# CTRL_MODULE_CORE register map
Vendor: Texas Instruments
Registers are 32-bit, access per field, reset 0x0 unless marked. A register's access mark holds for its fields unless they carry their own. Offsets are as the file gives them; [hi:lo] are bit positions; 'fields as' and 'values as' point back to an identical list.

## CTRL_MODULE_CORE (part 9 of 12)
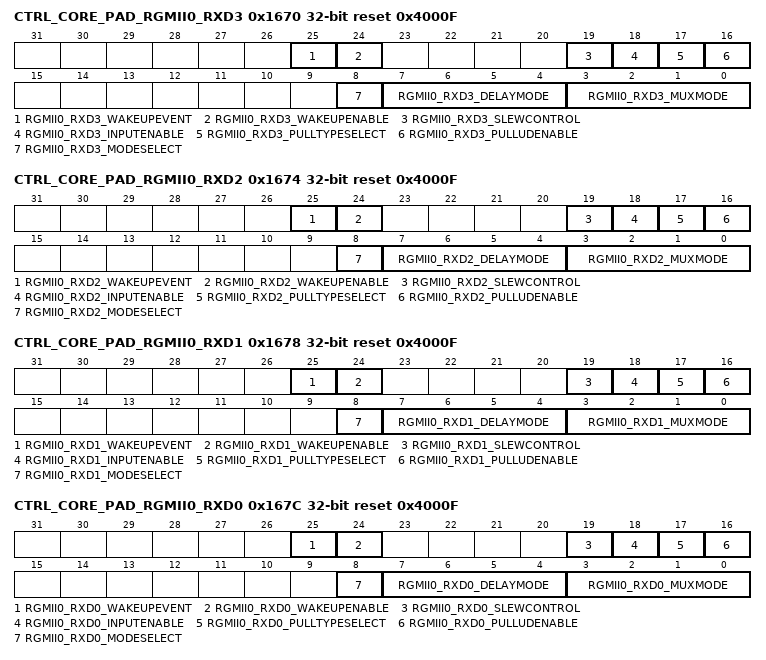
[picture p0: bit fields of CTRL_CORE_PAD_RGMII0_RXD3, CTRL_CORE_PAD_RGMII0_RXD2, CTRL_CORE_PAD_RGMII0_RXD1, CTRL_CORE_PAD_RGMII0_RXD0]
0x1670 CTRL_CORE_PAD_RGMII0_RXD3 reset 0x4000F
  [25] RGMII0_RXD3_WAKEUPEVENT ro
    0=NOWAKEUP (No wakeup event detected); 1=WAKEUP (Wakeup event detected)
  [24] RGMII0_RXD3_WAKEUPENABLE rw
    0=DISABLE (Wakeup is disabled); 1=ENABLE (Wakeup is enabled)
  [19] RGMII0_RXD3_SLEWCONTROL rw
    0=FAST_SLEW (Fast slew is selected); 1=SLOW_SLEW (Slow slew is selected)
  [18] RGMII0_RXD3_INPUTENABLE rw
    0=DISABLE (Receive mode is disabled); 1=ENABLE (Receive mode is enabled)
  [17] RGMII0_RXD3_PULLTYPESELECT rw
    0=PULL_DOWN (Pull Down is selected); 1=PULL_UP (Pull Up is selected)
  [16] RGMII0_RXD3_PULLUDENABLE rw
    0=ENABLE (Enables weak Pull Up/Down); 1=DISABLE (Disables weak Pull Up/Down)
  [8] RGMII0_RXD3_MODESELECT rw — Selects between the Default IO Timing Mode and a Virtual or Manual IO Timing Mode. Refer to the device Data Manual for definition of the required settings for a given mode of operation. When this bit is 0b1, a Virtual IO Timing Mode can be selected via the DELAYMODE field of this register, as described in, Virtual IO Timing Modes. Manual IO Timing Modes are selected via the procedure described in , Manual IO Timing Modes.
    0=MUX_MODE (Default IO Timing Mode is used); 1=DELAY_MODE (A Virtual or Manual IO Timing Mode is used)
  [7:4] RGMII0_RXD3_DELAYMODE rw — This bit field selects the Virtual Timing Mode used when the MODESELECT bit is set to 0b1. See, Virtual IO Timing Modes for details.
  [3:0] RGMII0_RXD3_MUXMODE rw
    0=RGMII0_RXD3; 2=RMII1_TXD0; 3=MII0_TXD2; 4=VIN2A_D7; 5=VIN4B_D7; 11=PR1_MII0_TXD2; 12=PR2_PRU1_GPI13; 13=PR2_PRU1_GPO13; 14=GPIO5_28; 15=DRIVER OFF
0x1674 CTRL_CORE_PAD_RGMII0_RXD2 reset 0x4000F
  [25] RGMII0_RXD2_WAKEUPEVENT ro
    values as CTRL_CORE_PAD_RGMII0_RXD3.RGMII0_RXD3_WAKEUPEVENT
  [24] RGMII0_RXD2_WAKEUPENABLE rw
    0=DISABLE (Wakeup is disabled); 1=ENABLE (Wakeup is enabled)
  [19] RGMII0_RXD2_SLEWCONTROL rw
    values as CTRL_CORE_PAD_RGMII0_RXD3.RGMII0_RXD3_SLEWCONTROL
  [18] RGMII0_RXD2_INPUTENABLE rw
    values as CTRL_CORE_PAD_RGMII0_RXD3.RGMII0_RXD3_INPUTENABLE
  [17] RGMII0_RXD2_PULLTYPESELECT rw
    values as CTRL_CORE_PAD_RGMII0_RXD3.RGMII0_RXD3_PULLTYPESELECT
  [16] RGMII0_RXD2_PULLUDENABLE rw
    values as CTRL_CORE_PAD_RGMII0_RXD3.RGMII0_RXD3_PULLUDENABLE
  [8] RGMII0_RXD2_MODESELECT rw — Selects between the Default IO Timing Mode and a Virtual or Manual IO Timing Mode. Refer to the device Data Manual for definition of the required settings for a given mode of operation. When this bit is 0b1, a Virtual IO Timing Mode can be selected via the DELAYMODE field of this register, as described in, Virtual IO Timing Modes. Manual IO Timing Modes are selected via the procedure described in , Manual IO Timing Modes.
    values as CTRL_CORE_PAD_RGMII0_RXD3.RGMII0_RXD3_MODESELECT
  [7:4] RGMII0_RXD2_DELAYMODE rw — This bit field selects the Virtual Timing Mode used when the MODESELECT bit is set to 0b1. See, Virtual IO Timing Modes for details.
  [3:0] RGMII0_RXD2_MUXMODE rw
    0=RGMII0_RXD2; 1=RMII0_TXEN; 3=MII0_TXEN; 4=VIN2A_D8; 11=PR1_MII0_TXEN; 12=PR2_PRU1_GPI14; 13=PR2_PRU1_GPO14; 14=GPIO5_29; 15=DRIVER OFF
0x1678 CTRL_CORE_PAD_RGMII0_RXD1 reset 0x4000F
  [25] RGMII0_RXD1_WAKEUPEVENT ro
    values as CTRL_CORE_PAD_RGMII0_RXD3.RGMII0_RXD3_WAKEUPEVENT
  [24] RGMII0_RXD1_WAKEUPENABLE rw
    0=DISABLE (Wakeup is disabled); 1=ENABLE (Wakeup is enabled)
  [19] RGMII0_RXD1_SLEWCONTROL rw
    values as CTRL_CORE_PAD_RGMII0_RXD3.RGMII0_RXD3_SLEWCONTROL
  [18] RGMII0_RXD1_INPUTENABLE rw
    values as CTRL_CORE_PAD_RGMII0_RXD3.RGMII0_RXD3_INPUTENABLE
  [17] RGMII0_RXD1_PULLTYPESELECT rw
    values as CTRL_CORE_PAD_RGMII0_RXD3.RGMII0_RXD3_PULLTYPESELECT
  [16] RGMII0_RXD1_PULLUDENABLE rw
    values as CTRL_CORE_PAD_RGMII0_RXD3.RGMII0_RXD3_PULLUDENABLE
  [8] RGMII0_RXD1_MODESELECT rw — Selects between the Default IO Timing Mode and a Virtual or Manual IO Timing Mode. Refer to the device Data Manual for definition of the required settings for a given mode of operation. When this bit is 0b1, a Virtual IO Timing Mode can be selected via the DELAYMODE field of this register, as described in, Virtual IO Timing Modes. Manual IO Timing Modes are selected via the procedure described in , Manual IO Timing Modes.
    values as CTRL_CORE_PAD_RGMII0_RXD3.RGMII0_RXD3_MODESELECT
  [7:4] RGMII0_RXD1_DELAYMODE rw — This bit field selects the Virtual Timing Mode used when the MODESELECT bit is set to 0b1. See, Virtual IO Timing Modes for details.
  [3:0] RGMII0_RXD1_MUXMODE rw
    0=RGMII0_RXD1; 1=RMII0_TXD1; 3=MII0_TXD1; 4=VIN2A_D9; 11=PR1_MII0_TXD1; 12=PR2_PRU1_GPI15; 13=PR2_PRU1_GPO15; 14=GPIO5_30; 15=DRIVER OFF
0x167C CTRL_CORE_PAD_RGMII0_RXD0 reset 0x4000F
  [25] RGMII0_RXD0_WAKEUPEVENT ro
    values as CTRL_CORE_PAD_RGMII0_RXD3.RGMII0_RXD3_WAKEUPEVENT
  [24] RGMII0_RXD0_WAKEUPENABLE rw
    0=DISABLE (Wakeup is disabled); 1=ENABLE (Wakeup is enabled)
  [19] RGMII0_RXD0_SLEWCONTROL rw
    values as CTRL_CORE_PAD_RGMII0_RXD3.RGMII0_RXD3_SLEWCONTROL
  [18] RGMII0_RXD0_INPUTENABLE rw
    values as CTRL_CORE_PAD_RGMII0_RXD3.RGMII0_RXD3_INPUTENABLE
  [17] RGMII0_RXD0_PULLTYPESELECT rw
    values as CTRL_CORE_PAD_RGMII0_RXD3.RGMII0_RXD3_PULLTYPESELECT
  [16] RGMII0_RXD0_PULLUDENABLE rw
    values as CTRL_CORE_PAD_RGMII0_RXD3.RGMII0_RXD3_PULLUDENABLE
  [8] RGMII0_RXD0_MODESELECT rw — Selects between the Default IO Timing Mode and a Virtual or Manual IO Timing Mode. Refer to the device Data Manual for definition of the required settings for a given mode of operation. When this bit is 0b1, a Virtual IO Timing Mode can be selected via the DELAYMODE field of this register, as described in, Virtual IO Timing Modes. Manual IO Timing Modes are selected via the procedure described in , Manual IO Timing Modes.
    values as CTRL_CORE_PAD_RGMII0_RXD3.RGMII0_RXD3_MODESELECT
  [7:4] RGMII0_RXD0_DELAYMODE rw — This bit field selects the Virtual Timing Mode used when the MODESELECT bit is set to 0b1. See, Virtual IO Timing Modes for details.
  [3:0] RGMII0_RXD0_MUXMODE rw
    0=RGMII0_RXD0; 1=RMII0_TXD0; 3=MII0_TXD0; 4=VIN2A_FLD0; 5=VIN4B_FLD1; 11=PR1_MII0_TXD0; 12=PR2_PRU1_GPI16; 13=PR2_PRU1_GPO16; 14=GPIO5_31; 15=DRIVER OFF
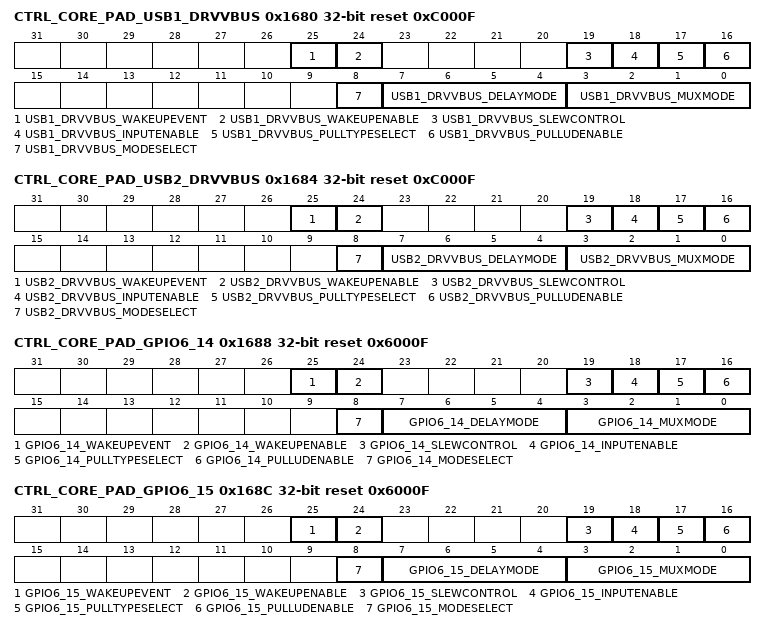
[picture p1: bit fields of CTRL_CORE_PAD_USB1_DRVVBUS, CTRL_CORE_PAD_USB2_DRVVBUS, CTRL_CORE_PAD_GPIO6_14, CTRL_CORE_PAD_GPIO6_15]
0x1680 CTRL_CORE_PAD_USB1_DRVVBUS reset 0xC000F
  [25] USB1_DRVVBUS_WAKEUPEVENT ro
    values as CTRL_CORE_PAD_RGMII0_RXD3.RGMII0_RXD3_WAKEUPEVENT
  [24] USB1_DRVVBUS_WAKEUPENABLE rw
    0=DISABLE (Wakeup is disabled); 1=ENABLE (Wakeup is enabled)
  [19] USB1_DRVVBUS_SLEWCONTROL rw
    values as CTRL_CORE_PAD_RGMII0_RXD3.RGMII0_RXD3_SLEWCONTROL
  [18] USB1_DRVVBUS_INPUTENABLE rw
    values as CTRL_CORE_PAD_RGMII0_RXD3.RGMII0_RXD3_INPUTENABLE
  [17] USB1_DRVVBUS_PULLTYPESELECT rw
    values as CTRL_CORE_PAD_RGMII0_RXD3.RGMII0_RXD3_PULLTYPESELECT
  [16] USB1_DRVVBUS_PULLUDENABLE rw
    values as CTRL_CORE_PAD_RGMII0_RXD3.RGMII0_RXD3_PULLUDENABLE
  [8] USB1_DRVVBUS_MODESELECT rw — Selects between the Default IO Timing Mode and a Virtual or Manual IO Timing Mode. Refer to the device Data Manual for definition of the required settings for a given mode of operation. When this bit is 0b1, a Virtual IO Timing Mode can be selected via the DELAYMODE field of this register, as described in, Virtual IO Timing Modes. Manual IO Timing Modes are selected via the procedure described in , Manual IO Timing Modes.
    values as CTRL_CORE_PAD_RGMII0_RXD3.RGMII0_RXD3_MODESELECT
  [7:4] USB1_DRVVBUS_DELAYMODE rw — This bit field selects the Virtual Timing Mode used when the MODESELECT bit is set to 0b1. See, Virtual IO Timing Modes for details.
  [3:0] USB1_DRVVBUS_MUXMODE rw
    0=USB1_DRVVBUS; 7=TIMER16; 14=GPIO6_12; 15=DRIVER OFF
0x1684 CTRL_CORE_PAD_USB2_DRVVBUS reset 0xC000F
  [25] USB2_DRVVBUS_WAKEUPEVENT ro
    values as CTRL_CORE_PAD_RGMII0_RXD3.RGMII0_RXD3_WAKEUPEVENT
  [24] USB2_DRVVBUS_WAKEUPENABLE rw
    0=DISABLE (Wakeup is disabled); 1=ENABLE (Wakeup is enabled)
  [19] USB2_DRVVBUS_SLEWCONTROL rw
    values as CTRL_CORE_PAD_RGMII0_RXD3.RGMII0_RXD3_SLEWCONTROL
  [18] USB2_DRVVBUS_INPUTENABLE rw
    values as CTRL_CORE_PAD_RGMII0_RXD3.RGMII0_RXD3_INPUTENABLE
  [17] USB2_DRVVBUS_PULLTYPESELECT rw
    values as CTRL_CORE_PAD_RGMII0_RXD3.RGMII0_RXD3_PULLTYPESELECT
  [16] USB2_DRVVBUS_PULLUDENABLE rw
    values as CTRL_CORE_PAD_RGMII0_RXD3.RGMII0_RXD3_PULLUDENABLE
  [8] USB2_DRVVBUS_MODESELECT rw — Selects between the Default IO Timing Mode and a Virtual or Manual IO Timing Mode. Refer to the device Data Manual for definition of the required settings for a given mode of operation. When this bit is 0b1, a Virtual IO Timing Mode can be selected via the DELAYMODE field of this register, as described in, Virtual IO Timing Modes. Manual IO Timing Modes are selected via the procedure described in , Manual IO Timing Modes.
    values as CTRL_CORE_PAD_RGMII0_RXD3.RGMII0_RXD3_MODESELECT
  [7:4] USB2_DRVVBUS_DELAYMODE rw — This bit field selects the Virtual Timing Mode used when the MODESELECT bit is set to 0b1. See, Virtual IO Timing Modes for details.
  [3:0] USB2_DRVVBUS_MUXMODE rw
    0=USB2_DRVVBUS; 7=TIMER15; 14=GPIO6_13; 15=DRIVER OFF
0x1688 CTRL_CORE_PAD_GPIO6_14 reset 0x6000F
  [25] GPIO6_14_WAKEUPEVENT ro
    values as CTRL_CORE_PAD_RGMII0_RXD3.RGMII0_RXD3_WAKEUPEVENT
  [24] GPIO6_14_WAKEUPENABLE rw
    0=DISABLE (Wakeup is disabled); 1=ENABLE (Wakeup is enabled)
  [19] GPIO6_14_SLEWCONTROL rw
    values as CTRL_CORE_PAD_RGMII0_RXD3.RGMII0_RXD3_SLEWCONTROL
  [18] GPIO6_14_INPUTENABLE rw
    values as CTRL_CORE_PAD_RGMII0_RXD3.RGMII0_RXD3_INPUTENABLE
  [17] GPIO6_14_PULLTYPESELECT rw
    values as CTRL_CORE_PAD_RGMII0_RXD3.RGMII0_RXD3_PULLTYPESELECT
  [16] GPIO6_14_PULLUDENABLE rw
    values as CTRL_CORE_PAD_RGMII0_RXD3.RGMII0_RXD3_PULLUDENABLE
  [8] GPIO6_14_MODESELECT rw — Selects between the Default IO Timing Mode and a Virtual or Manual IO Timing Mode. Refer to the device Data Manual for definition of the required settings for a given mode of operation. When this bit is 0b1, a Virtual IO Timing Mode can be selected via the DELAYMODE field of this register, as described in, Virtual IO Timing Modes. Manual IO Timing Modes are selected via the procedure described in , Manual IO Timing Modes.
    values as CTRL_CORE_PAD_RGMII0_RXD3.RGMII0_RXD3_MODESELECT
  [7:4] GPIO6_14_DELAYMODE rw — This bit field selects the Virtual Timing Mode used when the MODESELECT bit is set to 0b1. See, Virtual IO Timing Modes for details.
  [3:0] GPIO6_14_MUXMODE rw
    0=GPIO6_14; 1=MCASP1_AXR8; 2=DCAN2_TX; 3=UART10_RXD; 6=VOUT2_HSYNC; 8=VIN4A_HSYNC0; 9=I2C3_SDA; 10=TIMER1; 14=GPIO6_14; 15=DRIVER OFF
0x168C CTRL_CORE_PAD_GPIO6_15 reset 0x6000F
  [25] GPIO6_15_WAKEUPEVENT ro
    values as CTRL_CORE_PAD_RGMII0_RXD3.RGMII0_RXD3_WAKEUPEVENT
  [24] GPIO6_15_WAKEUPENABLE rw
    0=DISABLE (Wakeup is disabled); 1=ENABLE (Wakeup is enabled)
  [19] GPIO6_15_SLEWCONTROL rw
    values as CTRL_CORE_PAD_RGMII0_RXD3.RGMII0_RXD3_SLEWCONTROL
  [18] GPIO6_15_INPUTENABLE rw
    values as CTRL_CORE_PAD_RGMII0_RXD3.RGMII0_RXD3_INPUTENABLE
  [17] GPIO6_15_PULLTYPESELECT rw
    values as CTRL_CORE_PAD_RGMII0_RXD3.RGMII0_RXD3_PULLTYPESELECT
  [16] GPIO6_15_PULLUDENABLE rw
    values as CTRL_CORE_PAD_RGMII0_RXD3.RGMII0_RXD3_PULLUDENABLE
  [8] GPIO6_15_MODESELECT rw — Selects between the Default IO Timing Mode and a Virtual or Manual IO Timing Mode. Refer to the device Data Manual for definition of the required settings for a given mode of operation. When this bit is 0b1, a Virtual IO Timing Mode can be selected via the DELAYMODE field of this register, as described in, Virtual IO Timing Modes. Manual IO Timing Modes are selected via the procedure described in , Manual IO Timing Modes.
    values as CTRL_CORE_PAD_RGMII0_RXD3.RGMII0_RXD3_MODESELECT
  [7:4] GPIO6_15_DELAYMODE rw — This bit field selects the Virtual Timing Mode used when the MODESELECT bit is set to 0b1. See, Virtual IO Timing Modes for details.
  [3:0] GPIO6_15_MUXMODE rw
    0=GPIO6_15; 1=MCASP1_AXR9; 2=DCAN2_RX; 3=UART10_TXD; 6=VOUT2_VSYNC; 8=VIN4A_VSYNC0; 9=I2C3_SCL; 10=TIMER2; 14=GPIO6_15; 15=DRIVER OFF
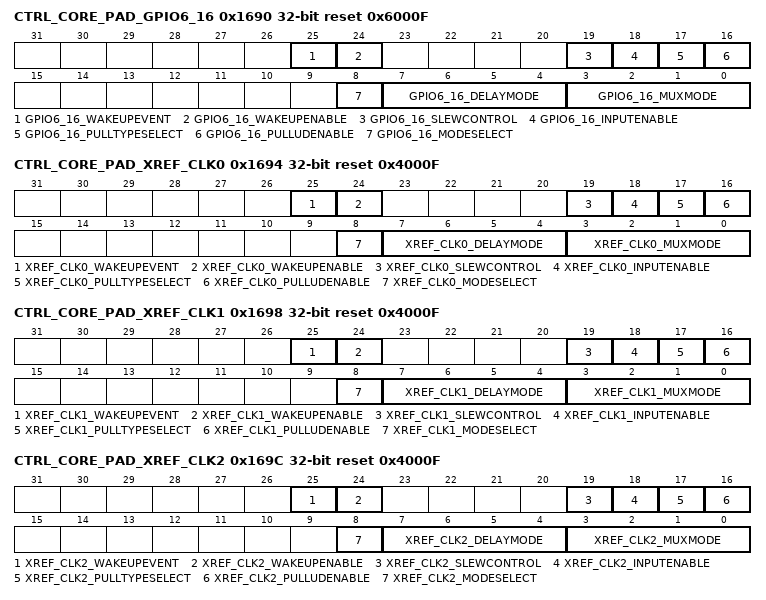
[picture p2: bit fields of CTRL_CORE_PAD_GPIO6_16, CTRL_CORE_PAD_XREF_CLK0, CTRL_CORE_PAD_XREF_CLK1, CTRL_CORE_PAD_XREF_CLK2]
0x1690 CTRL_CORE_PAD_GPIO6_16 reset 0x6000F
  [25] GPIO6_16_WAKEUPEVENT ro
    values as CTRL_CORE_PAD_RGMII0_RXD3.RGMII0_RXD3_WAKEUPEVENT
  [24] GPIO6_16_WAKEUPENABLE rw
    0=DISABLE (Wakeup is disabled); 1=ENABLE (Wakeup is enabled)
  [19] GPIO6_16_SLEWCONTROL rw
    values as CTRL_CORE_PAD_RGMII0_RXD3.RGMII0_RXD3_SLEWCONTROL
  [18] GPIO6_16_INPUTENABLE rw
    values as CTRL_CORE_PAD_RGMII0_RXD3.RGMII0_RXD3_INPUTENABLE
  [17] GPIO6_16_PULLTYPESELECT rw
    values as CTRL_CORE_PAD_RGMII0_RXD3.RGMII0_RXD3_PULLTYPESELECT
  [16] GPIO6_16_PULLUDENABLE rw
    values as CTRL_CORE_PAD_RGMII0_RXD3.RGMII0_RXD3_PULLUDENABLE
  [8] GPIO6_16_MODESELECT rw — Selects between the Default IO Timing Mode and a Virtual or Manual IO Timing Mode. Refer to the device Data Manual for definition of the required settings for a given mode of operation. When this bit is 0b1, a Virtual IO Timing Mode can be selected via the DELAYMODE field of this register, as described in, Virtual IO Timing Modes. Manual IO Timing Modes are selected via the procedure described in , Manual IO Timing Modes.
    values as CTRL_CORE_PAD_RGMII0_RXD3.RGMII0_RXD3_MODESELECT
  [7:4] GPIO6_16_DELAYMODE rw — This bit field selects the Virtual Timing Mode used when the MODESELECT bit is set to 0b1. See, Virtual IO Timing Modes for details.
  [3:0] GPIO6_16_MUXMODE rw
    0=GPIO6_16; 1=MCASP1_AXR10; 6=VOUT2_FLD; 8=VIN4A_FLD0; 9=CLKOUT1; 10=TIMER3; 14=GPIO6_16; 15=DRIVER OFF
0x1694 CTRL_CORE_PAD_XREF_CLK0 reset 0x4000F
  [25] XREF_CLK0_WAKEUPEVENT ro
    values as CTRL_CORE_PAD_RGMII0_RXD3.RGMII0_RXD3_WAKEUPEVENT
  [24] XREF_CLK0_WAKEUPENABLE rw
    0=DISABLE (Wakeup is disabled); 1=ENABLE (Wakeup is enabled)
  [19] XREF_CLK0_SLEWCONTROL rw
    values as CTRL_CORE_PAD_RGMII0_RXD3.RGMII0_RXD3_SLEWCONTROL
  [18] XREF_CLK0_INPUTENABLE rw
    values as CTRL_CORE_PAD_RGMII0_RXD3.RGMII0_RXD3_INPUTENABLE
  [17] XREF_CLK0_PULLTYPESELECT rw
    values as CTRL_CORE_PAD_RGMII0_RXD3.RGMII0_RXD3_PULLTYPESELECT
  [16] XREF_CLK0_PULLUDENABLE rw
    values as CTRL_CORE_PAD_RGMII0_RXD3.RGMII0_RXD3_PULLUDENABLE
  [8] XREF_CLK0_MODESELECT rw — Selects between the Default IO Timing Mode and a Virtual or Manual IO Timing Mode. Refer to the device Data Manual for definition of the required settings for a given mode of operation. When this bit is 0b1, a Virtual IO Timing Mode can be selected via the DELAYMODE field of this register, as described in, Virtual IO Timing Modes. Manual IO Timing Modes are selected via the procedure described in , Manual IO Timing Modes.
    values as CTRL_CORE_PAD_RGMII0_RXD3.RGMII0_RXD3_MODESELECT
  [7:4] XREF_CLK0_DELAYMODE rw — This bit field selects the Virtual Timing Mode used when the MODESELECT bit is set to 0b1. See, Virtual IO Timing Modes for details.
  [3:0] XREF_CLK0_MUXMODE rw
    0=XREF_CLK0; 1=MCASP2_AXR8; 2=MCASP1_AXR4; 3=MCASP1_AHCLKX; 4=MCASP5_AHCLKX; 7=VIN6A_D0; 8=HDQ0; 9=CLKOUT2; 10=TIMER13; 11=PR2_MII1_COL; 12=PR2_PRU1_GPI5; 13=PR2_PRU1_GPO5; 14=GPIO6_17; 15=DRIVER OFF
0x1698 CTRL_CORE_PAD_XREF_CLK1 reset 0x4000F
  [25] XREF_CLK1_WAKEUPEVENT ro
    values as CTRL_CORE_PAD_RGMII0_RXD3.RGMII0_RXD3_WAKEUPEVENT
  [24] XREF_CLK1_WAKEUPENABLE rw
    0=DISABLE (Wakeup is disabled); 1=ENABLE (Wakeup is enabled)
  [19] XREF_CLK1_SLEWCONTROL rw
    values as CTRL_CORE_PAD_RGMII0_RXD3.RGMII0_RXD3_SLEWCONTROL
  [18] XREF_CLK1_INPUTENABLE rw
    values as CTRL_CORE_PAD_RGMII0_RXD3.RGMII0_RXD3_INPUTENABLE
  [17] XREF_CLK1_PULLTYPESELECT rw
    values as CTRL_CORE_PAD_RGMII0_RXD3.RGMII0_RXD3_PULLTYPESELECT
  [16] XREF_CLK1_PULLUDENABLE rw
    values as CTRL_CORE_PAD_RGMII0_RXD3.RGMII0_RXD3_PULLUDENABLE
  [8] XREF_CLK1_MODESELECT rw — Selects between the Default IO Timing Mode and a Virtual or Manual IO Timing Mode. Refer to the device Data Manual for definition of the required settings for a given mode of operation. When this bit is 0b1, a Virtual IO Timing Mode can be selected via the DELAYMODE field of this register, as described in, Virtual IO Timing Modes. Manual IO Timing Modes are selected via the procedure described in , Manual IO Timing Modes.
    values as CTRL_CORE_PAD_RGMII0_RXD3.RGMII0_RXD3_MODESELECT
  [7:4] XREF_CLK1_DELAYMODE rw — This bit field selects the Virtual Timing Mode used when the MODESELECT bit is set to 0b1. See, Virtual IO Timing Modes for details.
  [3:0] XREF_CLK1_MUXMODE rw
    0=XREF_CLK1; 1=MCASP2_AXR9; 2=MCASP1_AXR5; 3=MCASP2_AHCLKX; 4=MCASP6_AHCLKX; 7=VIN6A_CLK0; 10=TIMER14; 11=PR2_MII1_CRS; 12=PR2_PRU1_GPI6; 13=PR2_PRU1_GPO6; 14=GPIO6_18; 15=DRIVER OFF
0x169C CTRL_CORE_PAD_XREF_CLK2 reset 0x4000F
  [25] XREF_CLK2_WAKEUPEVENT ro
    values as CTRL_CORE_PAD_RGMII0_RXD3.RGMII0_RXD3_WAKEUPEVENT
  [24] XREF_CLK2_WAKEUPENABLE rw
    0=DISABLE (Wakeup is disabled); 1=ENABLE (Wakeup is enabled)
  [19] XREF_CLK2_SLEWCONTROL rw
    values as CTRL_CORE_PAD_RGMII0_RXD3.RGMII0_RXD3_SLEWCONTROL
  [18] XREF_CLK2_INPUTENABLE rw
    values as CTRL_CORE_PAD_RGMII0_RXD3.RGMII0_RXD3_INPUTENABLE
  [17] XREF_CLK2_PULLTYPESELECT rw
    values as CTRL_CORE_PAD_RGMII0_RXD3.RGMII0_RXD3_PULLTYPESELECT
  [16] XREF_CLK2_PULLUDENABLE rw
    values as CTRL_CORE_PAD_RGMII0_RXD3.RGMII0_RXD3_PULLUDENABLE
  [8] XREF_CLK2_MODESELECT rw — Selects between the Default IO Timing Mode and a Virtual or Manual IO Timing Mode. Refer to the device Data Manual for definition of the required settings for a given mode of operation. When this bit is 0b1, a Virtual IO Timing Mode can be selected via the DELAYMODE field of this register, as described in, Virtual IO Timing Modes. Manual IO Timing Modes are selected via the procedure described in , Manual IO Timing Modes.
    values as CTRL_CORE_PAD_RGMII0_RXD3.RGMII0_RXD3_MODESELECT
  [7:4] XREF_CLK2_DELAYMODE rw — This bit field selects the Virtual Timing Mode used when the MODESELECT bit is set to 0b1. See, Virtual IO Timing Modes for details.
  [3:0] XREF_CLK2_MUXMODE rw
    0=XREF_CLK2; 1=MCASP2_AXR10; 2=MCASP1_AXR6; 3=MCASP3_AHCLKX; 4=MCASP7_AHCLKX; 6=VOUT2_CLK; 8=VIN4A_CLK0; 10=TIMER15; 14=GPIO6_19; 15=DRIVER OFF
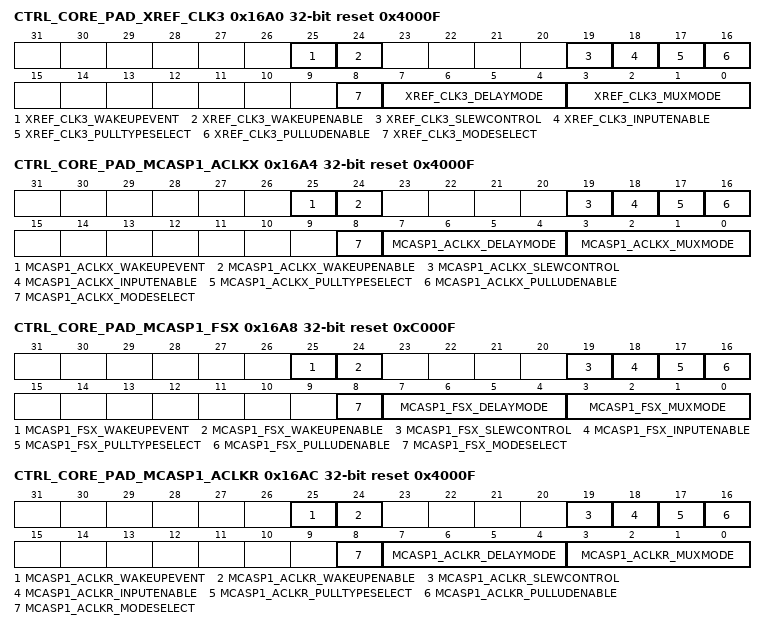
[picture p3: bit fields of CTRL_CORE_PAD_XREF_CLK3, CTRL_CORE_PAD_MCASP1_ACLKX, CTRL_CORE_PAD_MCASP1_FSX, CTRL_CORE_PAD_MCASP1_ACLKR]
0x16A0 CTRL_CORE_PAD_XREF_CLK3 reset 0x4000F
  [25] XREF_CLK3_WAKEUPEVENT ro
    values as CTRL_CORE_PAD_RGMII0_RXD3.RGMII0_RXD3_WAKEUPEVENT
  [24] XREF_CLK3_WAKEUPENABLE rw
    0=DISABLE (Wakeup is disabled); 1=ENABLE (Wakeup is enabled)
  [19] XREF_CLK3_SLEWCONTROL rw
    values as CTRL_CORE_PAD_RGMII0_RXD3.RGMII0_RXD3_SLEWCONTROL
  [18] XREF_CLK3_INPUTENABLE rw
    values as CTRL_CORE_PAD_RGMII0_RXD3.RGMII0_RXD3_INPUTENABLE
  [17] XREF_CLK3_PULLTYPESELECT rw
    values as CTRL_CORE_PAD_RGMII0_RXD3.RGMII0_RXD3_PULLTYPESELECT
  [16] XREF_CLK3_PULLUDENABLE rw
    values as CTRL_CORE_PAD_RGMII0_RXD3.RGMII0_RXD3_PULLUDENABLE
  [8] XREF_CLK3_MODESELECT rw — Selects between the Default IO Timing Mode and a Virtual or Manual IO Timing Mode. Refer to the device Data Manual for definition of the required settings for a given mode of operation. When this bit is 0b1, a Virtual IO Timing Mode can be selected via the DELAYMODE field of this register, as described in, Virtual IO Timing Modes. Manual IO Timing Modes are selected via the procedure described in , Manual IO Timing Modes.
    values as CTRL_CORE_PAD_RGMII0_RXD3.RGMII0_RXD3_MODESELECT
  [7:4] XREF_CLK3_DELAYMODE rw — This bit field selects the Virtual Timing Mode used when the MODESELECT bit is set to 0b1. See, Virtual IO Timing Modes for details.
  [3:0] XREF_CLK3_MUXMODE rw
    0=XREF_CLK3; 1=MCASP2_AXR11; 2=MCASP1_AXR7; 3=MCASP4_AHCLKX; 4=MCASP8_AHCLKX; 6=VOUT2_DE; 7=HDQ0; 8=VIN4A_DE0; 9=CLKOUT3; 10=TIMER16; 14=GPIO6_20; 15=DRIVER OFF
0x16A4 CTRL_CORE_PAD_MCASP1_ACLKX reset 0x4000F
  [25] MCASP1_ACLKX_WAKEUPEVENT ro
    values as CTRL_CORE_PAD_RGMII0_RXD3.RGMII0_RXD3_WAKEUPEVENT
  [24] MCASP1_ACLKX_WAKEUPENABLE rw
    0=DISABLE (Wakeup is disabled); 1=ENABLE (Wakeup is enabled)
  [19] MCASP1_ACLKX_SLEWCONTROL rw
    values as CTRL_CORE_PAD_RGMII0_RXD3.RGMII0_RXD3_SLEWCONTROL
  [18] MCASP1_ACLKX_INPUTENABLE rw
    values as CTRL_CORE_PAD_RGMII0_RXD3.RGMII0_RXD3_INPUTENABLE
  [17] MCASP1_ACLKX_PULLTYPESELECT rw
    values as CTRL_CORE_PAD_RGMII0_RXD3.RGMII0_RXD3_PULLTYPESELECT
  [16] MCASP1_ACLKX_PULLUDENABLE rw
    values as CTRL_CORE_PAD_RGMII0_RXD3.RGMII0_RXD3_PULLUDENABLE
  [8] MCASP1_ACLKX_MODESELECT rw — Selects between the Default IO Timing Mode and a Virtual or Manual IO Timing Mode. Refer to the device Data Manual for definition of the required settings for a given mode of operation. When this bit is 0b1, a Virtual IO Timing Mode can be selected via the DELAYMODE field of this register, as described in, Virtual IO Timing Modes. Manual IO Timing Modes are selected via the procedure described in , Manual IO Timing Modes.
    values as CTRL_CORE_PAD_RGMII0_RXD3.RGMII0_RXD3_MODESELECT
  [7:4] MCASP1_ACLKX_DELAYMODE rw — This bit field selects the Virtual Timing Mode used when the MODESELECT bit is set to 0b1. See, Virtual IO Timing Modes for details.
  [3:0] MCASP1_ACLKX_MUXMODE rw
    0=MCASP1_ACLKX; 7=VIN6A_FLD0; 10=I2C3_SDA; 11=PR2_MDIO_MDCLK; 12=PR2_PRU1_GPI7; 13=PR2_PRU1_GPO7; 14=GPIO7_31; 15=DRIVER OFF
0x16A8 CTRL_CORE_PAD_MCASP1_FSX reset 0xC000F
  [25] MCASP1_FSX_WAKEUPEVENT ro
    values as CTRL_CORE_PAD_RGMII0_RXD3.RGMII0_RXD3_WAKEUPEVENT
  [24] MCASP1_FSX_WAKEUPENABLE rw
    0=DISABLE (Wakeup is disabled); 1=ENABLE (Wakeup is enabled)
  [19] MCASP1_FSX_SLEWCONTROL rw
    values as CTRL_CORE_PAD_RGMII0_RXD3.RGMII0_RXD3_SLEWCONTROL
  [18] MCASP1_FSX_INPUTENABLE rw
    values as CTRL_CORE_PAD_RGMII0_RXD3.RGMII0_RXD3_INPUTENABLE
  [17] MCASP1_FSX_PULLTYPESELECT rw
    values as CTRL_CORE_PAD_RGMII0_RXD3.RGMII0_RXD3_PULLTYPESELECT
  [16] MCASP1_FSX_PULLUDENABLE rw
    values as CTRL_CORE_PAD_RGMII0_RXD3.RGMII0_RXD3_PULLUDENABLE
  [8] MCASP1_FSX_MODESELECT rw — Selects between the Default IO Timing Mode and a Virtual or Manual IO Timing Mode. Refer to the device Data Manual for definition of the required settings for a given mode of operation. When this bit is 0b1, a Virtual IO Timing Mode can be selected via the DELAYMODE field of this register, as described in, Virtual IO Timing Modes. Manual IO Timing Modes are selected via the procedure described in , Manual IO Timing Modes.
    values as CTRL_CORE_PAD_RGMII0_RXD3.RGMII0_RXD3_MODESELECT
  [7:4] MCASP1_FSX_DELAYMODE rw — This bit field selects the Virtual Timing Mode used when the MODESELECT bit is set to 0b1. See, Virtual IO Timing Modes for details.
  [3:0] MCASP1_FSX_MUXMODE rw
    0=MCASP1_FSX; 7=VIN6A_DE0; 10=I2C3_SCL; 11=PR2_MDIO_DATA; 14=GPIO7_30; 15=DRIVER OFF
0x16AC CTRL_CORE_PAD_MCASP1_ACLKR reset 0x4000F
  [25] MCASP1_ACLKR_WAKEUPEVENT ro
    values as CTRL_CORE_PAD_RGMII0_RXD3.RGMII0_RXD3_WAKEUPEVENT
  [24] MCASP1_ACLKR_WAKEUPENABLE rw
    0=DISABLE (Wakeup is disabled); 1=ENABLE (Wakeup is enabled)
  [19] MCASP1_ACLKR_SLEWCONTROL rw
    values as CTRL_CORE_PAD_RGMII0_RXD3.RGMII0_RXD3_SLEWCONTROL
  [18] MCASP1_ACLKR_INPUTENABLE rw
    values as CTRL_CORE_PAD_RGMII0_RXD3.RGMII0_RXD3_INPUTENABLE
  [17] MCASP1_ACLKR_PULLTYPESELECT rw
    values as CTRL_CORE_PAD_RGMII0_RXD3.RGMII0_RXD3_PULLTYPESELECT
  [16] MCASP1_ACLKR_PULLUDENABLE rw
    values as CTRL_CORE_PAD_RGMII0_RXD3.RGMII0_RXD3_PULLUDENABLE
  [8] MCASP1_ACLKR_MODESELECT rw — Selects between the Default IO Timing Mode and a Virtual or Manual IO Timing Mode. Refer to the device Data Manual for definition of the required settings for a given mode of operation. When this bit is 0b1, a Virtual IO Timing Mode can be selected via the DELAYMODE field of this register, as described in, Virtual IO Timing Modes. Manual IO Timing Modes are selected via the procedure described in , Manual IO Timing Modes.
    values as CTRL_CORE_PAD_RGMII0_RXD3.RGMII0_RXD3_MODESELECT
  [7:4] MCASP1_ACLKR_DELAYMODE rw — This bit field selects the Virtual Timing Mode used when the MODESELECT bit is set to 0b1. See, Virtual IO Timing Modes for details.
  [3:0] MCASP1_ACLKR_MUXMODE rw
    0=MCASP1_ACLKR; 1=MCASP7_AXR2; 6=VOUT2_D0; 8=VIN4A_D0; 10=I2C4_SDA; 14=GPIO5_0; 15=DRIVER OFF
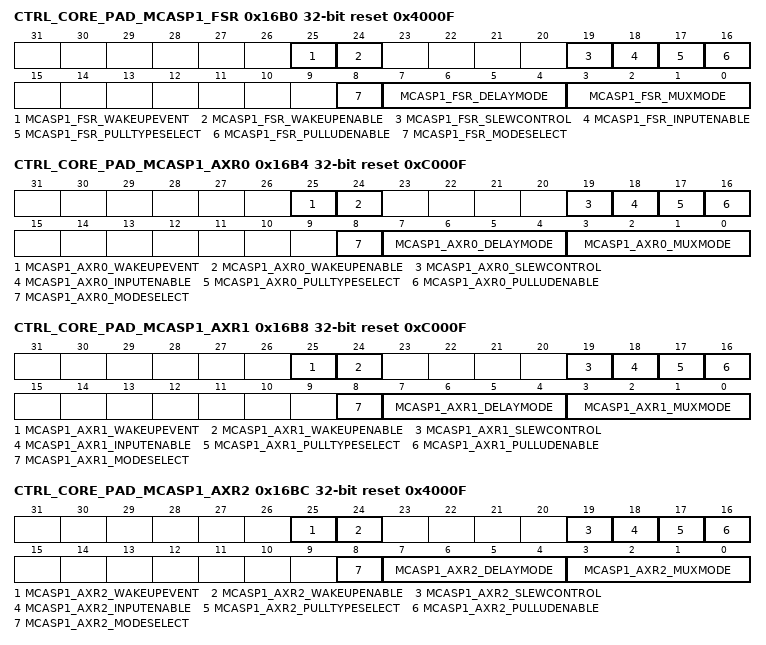
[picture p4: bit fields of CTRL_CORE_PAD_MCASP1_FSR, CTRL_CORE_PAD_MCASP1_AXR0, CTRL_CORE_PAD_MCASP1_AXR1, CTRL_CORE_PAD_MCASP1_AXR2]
0x16B0 CTRL_CORE_PAD_MCASP1_FSR reset 0x4000F
  [25] MCASP1_FSR_WAKEUPEVENT ro
    values as CTRL_CORE_PAD_RGMII0_RXD3.RGMII0_RXD3_WAKEUPEVENT
  [24] MCASP1_FSR_WAKEUPENABLE rw
    0=DISABLE (Wakeup is disabled); 1=ENABLE (Wakeup is enabled)
  [19] MCASP1_FSR_SLEWCONTROL rw
    values as CTRL_CORE_PAD_RGMII0_RXD3.RGMII0_RXD3_SLEWCONTROL
  [18] MCASP1_FSR_INPUTENABLE rw
    values as CTRL_CORE_PAD_RGMII0_RXD3.RGMII0_RXD3_INPUTENABLE
  [17] MCASP1_FSR_PULLTYPESELECT rw
    values as CTRL_CORE_PAD_RGMII0_RXD3.RGMII0_RXD3_PULLTYPESELECT
  [16] MCASP1_FSR_PULLUDENABLE rw
    values as CTRL_CORE_PAD_RGMII0_RXD3.RGMII0_RXD3_PULLUDENABLE
  [8] MCASP1_FSR_MODESELECT rw — Selects between the Default IO Timing Mode and a Virtual or Manual IO Timing Mode. Refer to the device Data Manual for definition of the required settings for a given mode of operation. When this bit is 0b1, a Virtual IO Timing Mode can be selected via the DELAYMODE field of this register, as described in, Virtual IO Timing Modes. Manual IO Timing Modes are selected via the procedure described in , Manual IO Timing Modes.
    values as CTRL_CORE_PAD_RGMII0_RXD3.RGMII0_RXD3_MODESELECT
  [7:4] MCASP1_FSR_DELAYMODE rw — This bit field selects the Virtual Timing Mode used when the MODESELECT bit is set to 0b1. See, Virtual IO Timing Modes for details.
  [3:0] MCASP1_FSR_MUXMODE rw
    0=MCASP1_FSR; 1=MCASP7_AXR3; 6=VOUT2_D1; 8=VIN4A_D1; 10=I2C4_SCL; 14=GPIO5_1; 15=DRIVER OFF
0x16B4 CTRL_CORE_PAD_MCASP1_AXR0 reset 0xC000F
  [25] MCASP1_AXR0_WAKEUPEVENT ro
    values as CTRL_CORE_PAD_RGMII0_RXD3.RGMII0_RXD3_WAKEUPEVENT
  [24] MCASP1_AXR0_WAKEUPENABLE rw
    0=DISABLE (Wakeup is disabled); 1=ENABLE (Wakeup is enabled)
  [19] MCASP1_AXR0_SLEWCONTROL rw
    values as CTRL_CORE_PAD_RGMII0_RXD3.RGMII0_RXD3_SLEWCONTROL
  [18] MCASP1_AXR0_INPUTENABLE rw
    values as CTRL_CORE_PAD_RGMII0_RXD3.RGMII0_RXD3_INPUTENABLE
  [17] MCASP1_AXR0_PULLTYPESELECT rw
    values as CTRL_CORE_PAD_RGMII0_RXD3.RGMII0_RXD3_PULLTYPESELECT
  [16] MCASP1_AXR0_PULLUDENABLE rw
    values as CTRL_CORE_PAD_RGMII0_RXD3.RGMII0_RXD3_PULLUDENABLE
  [8] MCASP1_AXR0_MODESELECT rw — Selects between the Default IO Timing Mode and a Virtual or Manual IO Timing Mode. Refer to the device Data Manual for definition of the required settings for a given mode of operation. When this bit is 0b1, a Virtual IO Timing Mode can be selected via the DELAYMODE field of this register, as described in, Virtual IO Timing Modes. Manual IO Timing Modes are selected via the procedure described in , Manual IO Timing Modes.
    values as CTRL_CORE_PAD_RGMII0_RXD3.RGMII0_RXD3_MODESELECT
  [7:4] MCASP1_AXR0_DELAYMODE rw — This bit field selects the Virtual Timing Mode used when the MODESELECT bit is set to 0b1. See, Virtual IO Timing Modes for details.
  [3:0] MCASP1_AXR0_MUXMODE rw
    0=MCASP1_AXR0; 3=UART6_RXD; 7=VIN6A_VSYNC0; 10=I2C5_SDA; 11=PR2_MII0_RXER; 12=PR2_PRU1_GPI8; 13=PR2_PRU1_GPO8; 14=GPIO5_2; 15=DRIVER OFF
0x16B8 CTRL_CORE_PAD_MCASP1_AXR1 reset 0xC000F
  [25] MCASP1_AXR1_WAKEUPEVENT ro
    values as CTRL_CORE_PAD_RGMII0_RXD3.RGMII0_RXD3_WAKEUPEVENT
  [24] MCASP1_AXR1_WAKEUPENABLE rw
    0=DISABLE (Wakeup is disabled); 1=ENABLE (Wakeup is enabled)
  [19] MCASP1_AXR1_SLEWCONTROL rw
    values as CTRL_CORE_PAD_RGMII0_RXD3.RGMII0_RXD3_SLEWCONTROL
  [18] MCASP1_AXR1_INPUTENABLE rw
    values as CTRL_CORE_PAD_RGMII0_RXD3.RGMII0_RXD3_INPUTENABLE
  [17] MCASP1_AXR1_PULLTYPESELECT rw
    values as CTRL_CORE_PAD_RGMII0_RXD3.RGMII0_RXD3_PULLTYPESELECT
  [16] MCASP1_AXR1_PULLUDENABLE rw
    values as CTRL_CORE_PAD_RGMII0_RXD3.RGMII0_RXD3_PULLUDENABLE
  [8] MCASP1_AXR1_MODESELECT rw — Selects between the Default IO Timing Mode and a Virtual or Manual IO Timing Mode. Refer to the device Data Manual for definition of the required settings for a given mode of operation. When this bit is 0b1, a Virtual IO Timing Mode can be selected via the DELAYMODE field of this register, as described in, Virtual IO Timing Modes. Manual IO Timing Modes are selected via the procedure described in , Manual IO Timing Modes.
    values as CTRL_CORE_PAD_RGMII0_RXD3.RGMII0_RXD3_MODESELECT
  [7:4] MCASP1_AXR1_DELAYMODE rw — This bit field selects the Virtual Timing Mode used when the MODESELECT bit is set to 0b1. See, Virtual IO Timing Modes for details.
  [3:0] MCASP1_AXR1_MUXMODE rw
    0=MCASP1_AXR1; 3=UART6_TXD; 7=VIN6A_HSYNC0; 10=I2C5_SCL; 11=PR2_MII_MT0_CLK; 12=PR2_PRU1_GPI9; 13=PR2_PRU1_GPO9; 14=GPIO5_3; 15=DRIVER OFF
0x16BC CTRL_CORE_PAD_MCASP1_AXR2 reset 0x4000F
  [25] MCASP1_AXR2_WAKEUPEVENT ro
    values as CTRL_CORE_PAD_RGMII0_RXD3.RGMII0_RXD3_WAKEUPEVENT
  [24] MCASP1_AXR2_WAKEUPENABLE rw
    0=DISABLE (Wakeup is disabled); 1=ENABLE (Wakeup is enabled)
  [19] MCASP1_AXR2_SLEWCONTROL rw
    values as CTRL_CORE_PAD_RGMII0_RXD3.RGMII0_RXD3_SLEWCONTROL
  [18] MCASP1_AXR2_INPUTENABLE rw
    values as CTRL_CORE_PAD_RGMII0_RXD3.RGMII0_RXD3_INPUTENABLE
  [17] MCASP1_AXR2_PULLTYPESELECT rw
    values as CTRL_CORE_PAD_RGMII0_RXD3.RGMII0_RXD3_PULLTYPESELECT
  [16] MCASP1_AXR2_PULLUDENABLE rw
    values as CTRL_CORE_PAD_RGMII0_RXD3.RGMII0_RXD3_PULLUDENABLE
  [8] MCASP1_AXR2_MODESELECT rw — Selects between the Default IO Timing Mode and a Virtual or Manual IO Timing Mode. Refer to the device Data Manual for definition of the required settings for a given mode of operation. When this bit is 0b1, a Virtual IO Timing Mode can be selected via the DELAYMODE field of this register, as described in, Virtual IO Timing Modes. Manual IO Timing Modes are selected via the procedure described in , Manual IO Timing Modes.
    values as CTRL_CORE_PAD_RGMII0_RXD3.RGMII0_RXD3_MODESELECT
  [7:4] MCASP1_AXR2_DELAYMODE rw — This bit field selects the Virtual Timing Mode used when the MODESELECT bit is set to 0b1. See, Virtual IO Timing Modes for details.
  [3:0] MCASP1_AXR2_MUXMODE rw
    0=MCASP1_AXR2; 1=MCASP6_AXR2; 3=UART6_CTSN; 6=VOUT2_D2; 8=VIN4A_D2; 14=GPIO5_4; 15=DRIVER OFF
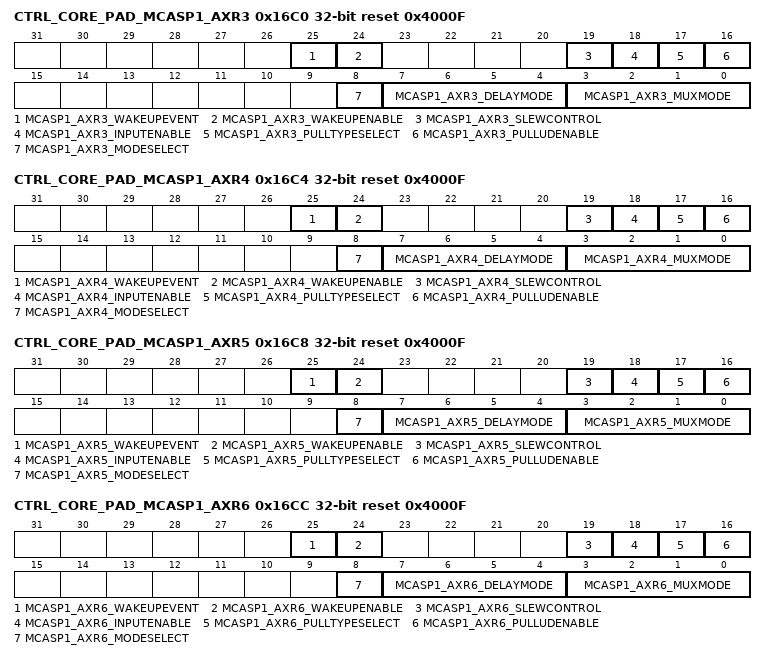
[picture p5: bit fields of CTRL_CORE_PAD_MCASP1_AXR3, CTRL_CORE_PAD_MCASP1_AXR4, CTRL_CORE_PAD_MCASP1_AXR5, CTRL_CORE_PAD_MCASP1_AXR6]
0x16C0 CTRL_CORE_PAD_MCASP1_AXR3 reset 0x4000F
  [25] MCASP1_AXR3_WAKEUPEVENT ro
    values as CTRL_CORE_PAD_RGMII0_RXD3.RGMII0_RXD3_WAKEUPEVENT
  [24] MCASP1_AXR3_WAKEUPENABLE rw
    0=DISABLE (Wakeup is disabled); 1=ENABLE (Wakeup is enabled)
  [19] MCASP1_AXR3_SLEWCONTROL rw
    values as CTRL_CORE_PAD_RGMII0_RXD3.RGMII0_RXD3_SLEWCONTROL
  [18] MCASP1_AXR3_INPUTENABLE rw
    values as CTRL_CORE_PAD_RGMII0_RXD3.RGMII0_RXD3_INPUTENABLE
  [17] MCASP1_AXR3_PULLTYPESELECT rw
    values as CTRL_CORE_PAD_RGMII0_RXD3.RGMII0_RXD3_PULLTYPESELECT
  [16] MCASP1_AXR3_PULLUDENABLE rw
    values as CTRL_CORE_PAD_RGMII0_RXD3.RGMII0_RXD3_PULLUDENABLE
  [8] MCASP1_AXR3_MODESELECT rw — Selects between the Default IO Timing Mode and a Virtual or Manual IO Timing Mode. Refer to the device Data Manual for definition of the required settings for a given mode of operation. When this bit is 0b1, a Virtual IO Timing Mode can be selected via the DELAYMODE field of this register, as described in, Virtual IO Timing Modes. Manual IO Timing Modes are selected via the procedure described in , Manual IO Timing Modes.
    values as CTRL_CORE_PAD_RGMII0_RXD3.RGMII0_RXD3_MODESELECT
  [7:4] MCASP1_AXR3_DELAYMODE rw — This bit field selects the Virtual Timing Mode used when the MODESELECT bit is set to 0b1. See, Virtual IO Timing Modes for details.
  [3:0] MCASP1_AXR3_MUXMODE rw
    0=MCASP1_AXR3; 1=MCASP6_AXR3; 3=UART6_RTSN; 6=VOUT2_D3; 8=VIN4A_D3; 14=GPIO5_5; 15=DRIVER OFF
0x16C4 CTRL_CORE_PAD_MCASP1_AXR4 reset 0x4000F
  [25] MCASP1_AXR4_WAKEUPEVENT ro
    values as CTRL_CORE_PAD_RGMII0_RXD3.RGMII0_RXD3_WAKEUPEVENT
  [24] MCASP1_AXR4_WAKEUPENABLE rw
    0=DISABLE (Wakeup is disabled); 1=ENABLE (Wakeup is enabled)
  [19] MCASP1_AXR4_SLEWCONTROL rw
    values as CTRL_CORE_PAD_RGMII0_RXD3.RGMII0_RXD3_SLEWCONTROL
  [18] MCASP1_AXR4_INPUTENABLE rw
    values as CTRL_CORE_PAD_RGMII0_RXD3.RGMII0_RXD3_INPUTENABLE
  [17] MCASP1_AXR4_PULLTYPESELECT rw
    values as CTRL_CORE_PAD_RGMII0_RXD3.RGMII0_RXD3_PULLTYPESELECT
  [16] MCASP1_AXR4_PULLUDENABLE rw
    values as CTRL_CORE_PAD_RGMII0_RXD3.RGMII0_RXD3_PULLUDENABLE
  [8] MCASP1_AXR4_MODESELECT rw — Selects between the Default IO Timing Mode and a Virtual or Manual IO Timing Mode. Refer to the device Data Manual for definition of the required settings for a given mode of operation. When this bit is 0b1, a Virtual IO Timing Mode can be selected via the DELAYMODE field of this register, as described in, Virtual IO Timing Modes. Manual IO Timing Modes are selected via the procedure described in , Manual IO Timing Modes.
    values as CTRL_CORE_PAD_RGMII0_RXD3.RGMII0_RXD3_MODESELECT
  [7:4] MCASP1_AXR4_DELAYMODE rw — This bit field selects the Virtual Timing Mode used when the MODESELECT bit is set to 0b1. See, Virtual IO Timing Modes for details.
  [3:0] MCASP1_AXR4_MUXMODE rw
    0=MCASP1_AXR4; 1=MCASP4_AXR2; 6=VOUT2_D4; 8=VIN4A_D4; 14=GPIO5_6; 15=DRIVER OFF
0x16C8 CTRL_CORE_PAD_MCASP1_AXR5 reset 0x4000F
  [25] MCASP1_AXR5_WAKEUPEVENT ro
    values as CTRL_CORE_PAD_RGMII0_RXD3.RGMII0_RXD3_WAKEUPEVENT
  [24] MCASP1_AXR5_WAKEUPENABLE rw
    0=DISABLE (Wakeup is disabled); 1=ENABLE (Wakeup is enabled)
  [19] MCASP1_AXR5_SLEWCONTROL rw
    values as CTRL_CORE_PAD_RGMII0_RXD3.RGMII0_RXD3_SLEWCONTROL
  [18] MCASP1_AXR5_INPUTENABLE rw
    values as CTRL_CORE_PAD_RGMII0_RXD3.RGMII0_RXD3_INPUTENABLE
  [17] MCASP1_AXR5_PULLTYPESELECT rw
    values as CTRL_CORE_PAD_RGMII0_RXD3.RGMII0_RXD3_PULLTYPESELECT
  [16] MCASP1_AXR5_PULLUDENABLE rw
    values as CTRL_CORE_PAD_RGMII0_RXD3.RGMII0_RXD3_PULLUDENABLE
  [8] MCASP1_AXR5_MODESELECT rw — Selects between the Default IO Timing Mode and a Virtual or Manual IO Timing Mode. Refer to the device Data Manual for definition of the required settings for a given mode of operation. When this bit is 0b1, a Virtual IO Timing Mode can be selected via the DELAYMODE field of this register, as described in, Virtual IO Timing Modes. Manual IO Timing Modes are selected via the procedure described in , Manual IO Timing Modes.
    values as CTRL_CORE_PAD_RGMII0_RXD3.RGMII0_RXD3_MODESELECT
  [7:4] MCASP1_AXR5_DELAYMODE rw — This bit field selects the Virtual Timing Mode used when the MODESELECT bit is set to 0b1. See, Virtual IO Timing Modes for details.
  [3:0] MCASP1_AXR5_MUXMODE rw
    0=MCASP1_AXR5; 1=MCASP4_AXR3; 6=VOUT2_D5; 8=VIN4A_D5; 14=GPIO5_7; 15=DRIVER OFF
0x16CC CTRL_CORE_PAD_MCASP1_AXR6 reset 0x4000F
  [25] MCASP1_AXR6_WAKEUPEVENT ro
    values as CTRL_CORE_PAD_RGMII0_RXD3.RGMII0_RXD3_WAKEUPEVENT
  [24] MCASP1_AXR6_WAKEUPENABLE rw
    0=DISABLE (Wakeup is disabled); 1=ENABLE (Wakeup is enabled)
  [19] MCASP1_AXR6_SLEWCONTROL rw
    values as CTRL_CORE_PAD_RGMII0_RXD3.RGMII0_RXD3_SLEWCONTROL
  [18] MCASP1_AXR6_INPUTENABLE rw
    values as CTRL_CORE_PAD_RGMII0_RXD3.RGMII0_RXD3_INPUTENABLE
  [17] MCASP1_AXR6_PULLTYPESELECT rw
    values as CTRL_CORE_PAD_RGMII0_RXD3.RGMII0_RXD3_PULLTYPESELECT
  [16] MCASP1_AXR6_PULLUDENABLE rw
    values as CTRL_CORE_PAD_RGMII0_RXD3.RGMII0_RXD3_PULLUDENABLE
  [8] MCASP1_AXR6_MODESELECT rw — Selects between the Default IO Timing Mode and a Virtual or Manual IO Timing Mode. Refer to the device Data Manual for definition of the required settings for a given mode of operation. When this bit is 0b1, a Virtual IO Timing Mode can be selected via the DELAYMODE field of this register, as described in, Virtual IO Timing Modes. Manual IO Timing Modes are selected via the procedure described in , Manual IO Timing Modes.
    values as CTRL_CORE_PAD_RGMII0_RXD3.RGMII0_RXD3_MODESELECT
  [7:4] MCASP1_AXR6_DELAYMODE rw — This bit field selects the Virtual Timing Mode used when the MODESELECT bit is set to 0b1. See, Virtual IO Timing Modes for details.
  [3:0] MCASP1_AXR6_MUXMODE rw
    0=MCASP1_AXR6; 1=MCASP5_AXR2; 6=VOUT2_D6; 8=VIN4A_D6; 14=GPIO5_8; 15=DRIVER OFF
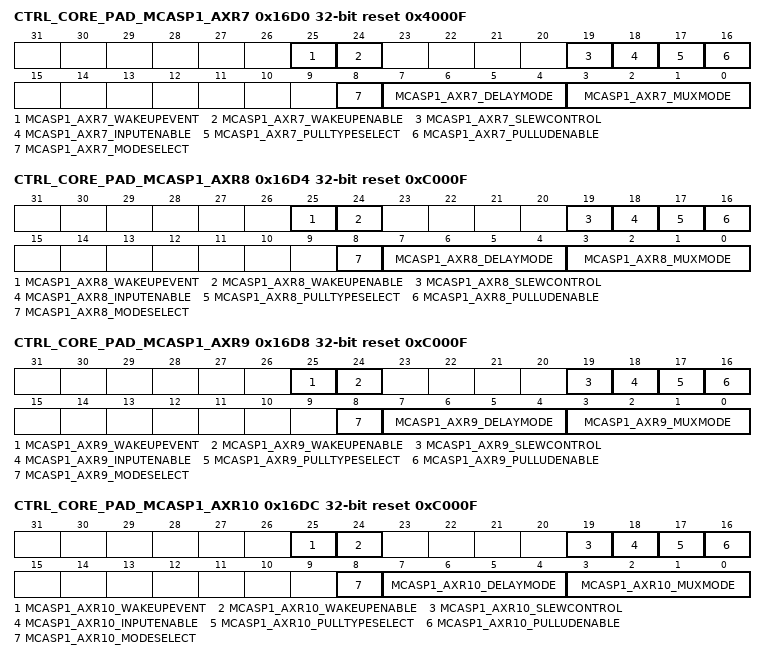
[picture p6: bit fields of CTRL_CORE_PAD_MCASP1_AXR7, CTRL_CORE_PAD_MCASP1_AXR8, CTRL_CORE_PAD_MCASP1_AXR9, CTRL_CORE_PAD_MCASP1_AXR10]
0x16D0 CTRL_CORE_PAD_MCASP1_AXR7 reset 0x4000F
  [25] MCASP1_AXR7_WAKEUPEVENT ro
    values as CTRL_CORE_PAD_RGMII0_RXD3.RGMII0_RXD3_WAKEUPEVENT
  [24] MCASP1_AXR7_WAKEUPENABLE rw
    0=DISABLE (Wakeup is disabled); 1=ENABLE (Wakeup is enabled)
  [19] MCASP1_AXR7_SLEWCONTROL rw
    values as CTRL_CORE_PAD_RGMII0_RXD3.RGMII0_RXD3_SLEWCONTROL
  [18] MCASP1_AXR7_INPUTENABLE rw
    values as CTRL_CORE_PAD_RGMII0_RXD3.RGMII0_RXD3_INPUTENABLE
  [17] MCASP1_AXR7_PULLTYPESELECT rw
    values as CTRL_CORE_PAD_RGMII0_RXD3.RGMII0_RXD3_PULLTYPESELECT
  [16] MCASP1_AXR7_PULLUDENABLE rw
    values as CTRL_CORE_PAD_RGMII0_RXD3.RGMII0_RXD3_PULLUDENABLE
  [8] MCASP1_AXR7_MODESELECT rw — Selects between the Default IO Timing Mode and a Virtual or Manual IO Timing Mode. Refer to the device Data Manual for definition of the required settings for a given mode of operation. When this bit is 0b1, a Virtual IO Timing Mode can be selected via the DELAYMODE field of this register, as described in, Virtual IO Timing Modes. Manual IO Timing Modes are selected via the procedure described in , Manual IO Timing Modes.
    values as CTRL_CORE_PAD_RGMII0_RXD3.RGMII0_RXD3_MODESELECT
  [7:4] MCASP1_AXR7_DELAYMODE rw — This bit field selects the Virtual Timing Mode used when the MODESELECT bit is set to 0b1. See, Virtual IO Timing Modes for details.
  [3:0] MCASP1_AXR7_MUXMODE rw
    0=MCASP1_AXR7; 1=MCASP5_AXR3; 6=VOUT2_D7; 8=VIN4A_D7; 10=TIMER4; 14=GPIO5_9; 15=DRIVER OFF
0x16D4 CTRL_CORE_PAD_MCASP1_AXR8 reset 0xC000F
  [25] MCASP1_AXR8_WAKEUPEVENT ro
    values as CTRL_CORE_PAD_RGMII0_RXD3.RGMII0_RXD3_WAKEUPEVENT
  [24] MCASP1_AXR8_WAKEUPENABLE rw
    0=DISABLE (Wakeup is disabled); 1=ENABLE (Wakeup is enabled)
  [19] MCASP1_AXR8_SLEWCONTROL rw
    values as CTRL_CORE_PAD_RGMII0_RXD3.RGMII0_RXD3_SLEWCONTROL
  [18] MCASP1_AXR8_INPUTENABLE rw
    values as CTRL_CORE_PAD_RGMII0_RXD3.RGMII0_RXD3_INPUTENABLE
  [17] MCASP1_AXR8_PULLTYPESELECT rw
    values as CTRL_CORE_PAD_RGMII0_RXD3.RGMII0_RXD3_PULLTYPESELECT
  [16] MCASP1_AXR8_PULLUDENABLE rw
    values as CTRL_CORE_PAD_RGMII0_RXD3.RGMII0_RXD3_PULLUDENABLE
  [8] MCASP1_AXR8_MODESELECT rw — Selects between the Default IO Timing Mode and a Virtual or Manual IO Timing Mode. Refer to the device Data Manual for definition of the required settings for a given mode of operation. When this bit is 0b1, a Virtual IO Timing Mode can be selected via the DELAYMODE field of this register, as described in, Virtual IO Timing Modes. Manual IO Timing Modes are selected via the procedure described in , Manual IO Timing Modes.
    values as CTRL_CORE_PAD_RGMII0_RXD3.RGMII0_RXD3_MODESELECT
  [7:4] MCASP1_AXR8_DELAYMODE rw — This bit field selects the Virtual Timing Mode used when the MODESELECT bit is set to 0b1. See, Virtual IO Timing Modes for details.
  [3:0] MCASP1_AXR8_MUXMODE rw
    0=MCASP1_AXR8; 1=MCASP6_AXR0; 3=SPI3_SCLK; 7=VIN6A_D15; 10=TIMER5; 11=PR2_MII0_TXEN; 12=PR2_PRU1_GPI10; 13=PR2_PRU1_GPO10; 14=GPIO5_10; 15=DRIVER OFF
0x16D8 CTRL_CORE_PAD_MCASP1_AXR9 reset 0xC000F
  [25] MCASP1_AXR9_WAKEUPEVENT ro
    values as CTRL_CORE_PAD_RGMII0_RXD3.RGMII0_RXD3_WAKEUPEVENT
  [24] MCASP1_AXR9_WAKEUPENABLE rw
    0=DISABLE (Wakeup is disabled); 1=ENABLE (Wakeup is enabled)
  [19] MCASP1_AXR9_SLEWCONTROL rw
    values as CTRL_CORE_PAD_RGMII0_RXD3.RGMII0_RXD3_SLEWCONTROL
  [18] MCASP1_AXR9_INPUTENABLE rw
    values as CTRL_CORE_PAD_RGMII0_RXD3.RGMII0_RXD3_INPUTENABLE
  [17] MCASP1_AXR9_PULLTYPESELECT rw
    values as CTRL_CORE_PAD_RGMII0_RXD3.RGMII0_RXD3_PULLTYPESELECT
  [16] MCASP1_AXR9_PULLUDENABLE rw
    values as CTRL_CORE_PAD_RGMII0_RXD3.RGMII0_RXD3_PULLUDENABLE
  [8] MCASP1_AXR9_MODESELECT rw — Selects between the Default IO Timing Mode and a Virtual or Manual IO Timing Mode. Refer to the device Data Manual for definition of the required settings for a given mode of operation. When this bit is 0b1, a Virtual IO Timing Mode can be selected via the DELAYMODE field of this register, as described in, Virtual IO Timing Modes. Manual IO Timing Modes are selected via the procedure described in , Manual IO Timing Modes.
    values as CTRL_CORE_PAD_RGMII0_RXD3.RGMII0_RXD3_MODESELECT
  [7:4] MCASP1_AXR9_DELAYMODE rw — This bit field selects the Virtual Timing Mode used when the MODESELECT bit is set to 0b1. See, Virtual IO Timing Modes for details.
  [3:0] MCASP1_AXR9_MUXMODE rw
    0=MCASP1_AXR9; 1=MCASP6_AXR1; 3=SPI3_D1; 7=VIN6A_D14; 10=TIMER6; 11=PR2_MII0_TXD3; 12=PR2_PRU1_GPI11; 13=PR2_PRU1_GPO11; 14=GPIO5_11; 15=DRIVER OFF
0x16DC CTRL_CORE_PAD_MCASP1_AXR10 reset 0xC000F
  [25] MCASP1_AXR10_WAKEUPEVENT ro
    values as CTRL_CORE_PAD_RGMII0_RXD3.RGMII0_RXD3_WAKEUPEVENT
  [24] MCASP1_AXR10_WAKEUPENABLE rw
    0=DISABLE (Wakeup is disabled); 1=ENABLE (Wakeup is enabled)
  [19] MCASP1_AXR10_SLEWCONTROL rw
    values as CTRL_CORE_PAD_RGMII0_RXD3.RGMII0_RXD3_SLEWCONTROL
  [18] MCASP1_AXR10_INPUTENABLE rw
    values as CTRL_CORE_PAD_RGMII0_RXD3.RGMII0_RXD3_INPUTENABLE
  [17] MCASP1_AXR10_PULLTYPESELECT rw
    values as CTRL_CORE_PAD_RGMII0_RXD3.RGMII0_RXD3_PULLTYPESELECT
  [16] MCASP1_AXR10_PULLUDENABLE rw
    values as CTRL_CORE_PAD_RGMII0_RXD3.RGMII0_RXD3_PULLUDENABLE
  [8] MCASP1_AXR10_MODESELECT rw — Selects between the Default IO Timing Mode and a Virtual or Manual IO Timing Mode. Refer to the device Data Manual for definition of the required settings for a given mode of operation. When this bit is 0b1, a Virtual IO Timing Mode can be selected via the DELAYMODE field of this register, as described in, Virtual IO Timing Modes. Manual IO Timing Modes are selected via the procedure described in , Manual IO Timing Modes.
    values as CTRL_CORE_PAD_RGMII0_RXD3.RGMII0_RXD3_MODESELECT
  [7:4] MCASP1_AXR10_DELAYMODE rw — This bit field selects the Virtual Timing Mode used when the MODESELECT bit is set to 0b1. See, Virtual IO Timing Modes for details.
  [3:0] MCASP1_AXR10_MUXMODE rw
    0=MCASP1_AXR10; 1=MCASP6_ACLKX; 2=MCASP6_ACLKR; 3=SPI3_D0; 7=VIN6A_D13; 10=TIMER7; 11=PR2_MII0_TXD2; 12=PR2_PRU1_GPI12; 13=PR2_PRU1_GPO12; 14=GPIO5_12; 15=DRIVER OFF
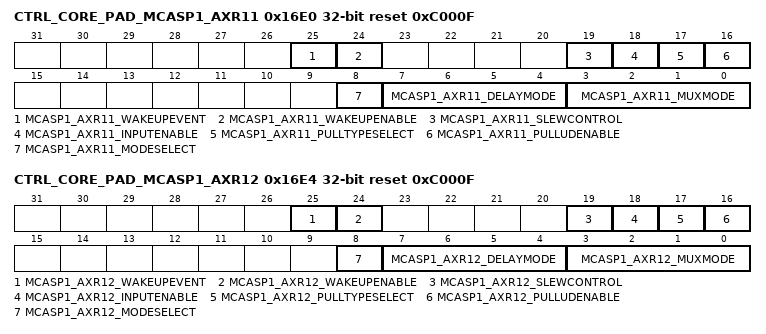
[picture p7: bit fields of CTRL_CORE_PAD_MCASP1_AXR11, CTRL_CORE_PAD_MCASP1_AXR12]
0x16E0 CTRL_CORE_PAD_MCASP1_AXR11 reset 0xC000F
  [25] MCASP1_AXR11_WAKEUPEVENT ro
    values as CTRL_CORE_PAD_RGMII0_RXD3.RGMII0_RXD3_WAKEUPEVENT
  [24] MCASP1_AXR11_WAKEUPENABLE rw
    0=DISABLE (Wakeup is disabled); 1=ENABLE (Wakeup is enabled)
  [19] MCASP1_AXR11_SLEWCONTROL rw
    values as CTRL_CORE_PAD_RGMII0_RXD3.RGMII0_RXD3_SLEWCONTROL
  [18] MCASP1_AXR11_INPUTENABLE rw
    values as CTRL_CORE_PAD_RGMII0_RXD3.RGMII0_RXD3_INPUTENABLE
  [17] MCASP1_AXR11_PULLTYPESELECT rw
    values as CTRL_CORE_PAD_RGMII0_RXD3.RGMII0_RXD3_PULLTYPESELECT
  [16] MCASP1_AXR11_PULLUDENABLE rw
    values as CTRL_CORE_PAD_RGMII0_RXD3.RGMII0_RXD3_PULLUDENABLE
  [8] MCASP1_AXR11_MODESELECT rw — Selects between the Default IO Timing Mode and a Virtual or Manual IO Timing Mode. Refer to the device Data Manual for definition of the required settings for a given mode of operation. When this bit is 0b1, a Virtual IO Timing Mode can be selected via the DELAYMODE field of this register, as described in, Virtual IO Timing Modes. Manual IO Timing Modes are selected via the procedure described in , Manual IO Timing Modes.
    values as CTRL_CORE_PAD_RGMII0_RXD3.RGMII0_RXD3_MODESELECT
  [7:4] MCASP1_AXR11_DELAYMODE rw — This bit field selects the Virtual Timing Mode used when the MODESELECT bit is set to 0b1. See, Virtual IO Timing Modes for details.
  [3:0] MCASP1_AXR11_MUXMODE rw
    0=MCASP1_AXR11; 1=MCASP6_FSX; 2=MCASP6_FSR; 3=SPI3_CS0; 7=VIN6A_D12; 10=TIMER8; 11=PR2_MII0_TXD1; 12=PR2_PRU1_GPI13; 13=PR2_PRU1_GPO13; 14=GPIO4_17; 15=DRIVER OFF
0x16E4 CTRL_CORE_PAD_MCASP1_AXR12 reset 0xC000F
  [25] MCASP1_AXR12_WAKEUPEVENT ro
    values as CTRL_CORE_PAD_RGMII0_RXD3.RGMII0_RXD3_WAKEUPEVENT
  [24] MCASP1_AXR12_WAKEUPENABLE rw
    0=DISABLE (Wakeup is disabled); 1=ENABLE (Wakeup is enabled)
  [19] MCASP1_AXR12_SLEWCONTROL rw
    values as CTRL_CORE_PAD_RGMII0_RXD3.RGMII0_RXD3_SLEWCONTROL
  [18] MCASP1_AXR12_INPUTENABLE rw
    values as CTRL_CORE_PAD_RGMII0_RXD3.RGMII0_RXD3_INPUTENABLE
  [17] MCASP1_AXR12_PULLTYPESELECT rw
    values as CTRL_CORE_PAD_RGMII0_RXD3.RGMII0_RXD3_PULLTYPESELECT
  [16] MCASP1_AXR12_PULLUDENABLE rw
    values as CTRL_CORE_PAD_RGMII0_RXD3.RGMII0_RXD3_PULLUDENABLE
  [8] MCASP1_AXR12_MODESELECT rw — Selects between the Default IO Timing Mode and a Virtual or Manual IO Timing Mode. Refer to the device Data Manual for definition of the required settings for a given mode of operation. When this bit is 0b1, a Virtual IO Timing Mode can be selected via the DELAYMODE field of this register, as described in, Virtual IO Timing Modes. Manual IO Timing Modes are selected via the procedure described in , Manual IO Timing Modes.
    values as CTRL_CORE_PAD_RGMII0_RXD3.RGMII0_RXD3_MODESELECT
  [7:4] MCASP1_AXR12_DELAYMODE rw — This bit field selects the Virtual Timing Mode used when the MODESELECT bit is set to 0b1. See, Virtual IO Timing Modes for details.
  [3:0] MCASP1_AXR12_MUXMODE rw
    0=MCASP1_AXR12; 1=MCASP7_AXR0; 3=SPI3_CS1; 7=VIN6A_D11; 10=TIMER9; 11=PR2_MII0_TXD0; 12=PR2_PRU1_GPI14; 13=PR2_PRU1_GPO14; 14=GPIO4_18; 15=DRIVER OFF
